# ESP32-S3 register map
Vendor: ESPRESSIF SYSTEMS (SHANGHAI) CO., LTD.; Series: ESP32 S-Series; File version: 22
CPU: Xtensa LX7 r0p0, little endian, no MPU, FPU, 0 interrupt priority bits
Address unit: 32 bits
Registers are 32-bit, read-write, reset 0x0 unless marked. A register's access mark holds for its fields unless they carry their own. Offsets are from the block's base; [hi:lo] are bit positions; {n}, {i} and the like mark numbered series.

## ASSIST_DEBUG — Debug Assist
Base 0x600CE000
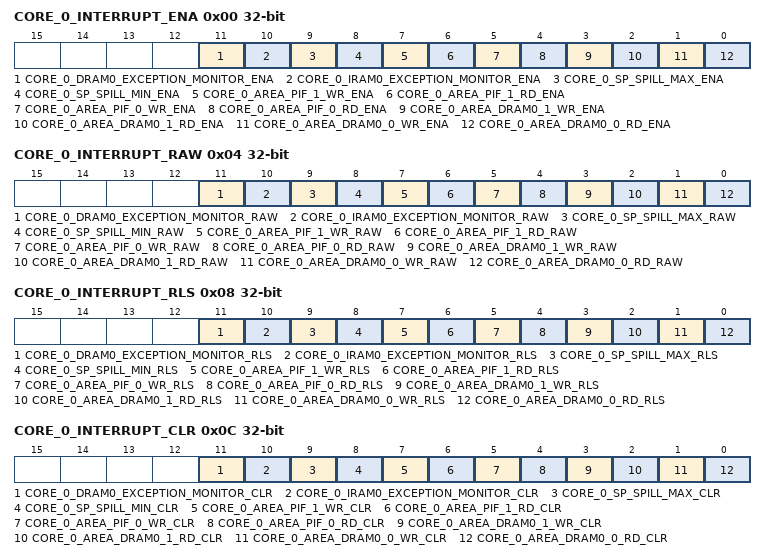
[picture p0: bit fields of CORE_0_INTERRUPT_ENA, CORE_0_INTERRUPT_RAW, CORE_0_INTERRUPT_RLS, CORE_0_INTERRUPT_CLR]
0x00 CORE_0_INTERRUPT_ENA — core0 monitor enable configuration register
  [11] CORE_0_DRAM0_EXCEPTION_MONITOR_ENA — DBUS busy monitor enbale
  [10] CORE_0_IRAM0_EXCEPTION_MONITOR_ENA — IBUS busy monitor enable
  [9] CORE_0_SP_SPILL_MAX_ENA — Core0 stackpoint underflow monitor enable
  [8] CORE_0_SP_SPILL_MIN_ENA — Core0 stackpoint overflow monitor enable
  [7] CORE_0_AREA_PIF_1_WR_ENA — Core0 PIF area1 write monitor enable
  [6] CORE_0_AREA_PIF_1_RD_ENA — Core0 PIF area1 read monitor enable
  [5] CORE_0_AREA_PIF_0_WR_ENA — Core0 PIF area0 write monitor enable
  [4] CORE_0_AREA_PIF_0_RD_ENA — Core0 PIF area0 read monitor enable
  [3] CORE_0_AREA_DRAM0_1_WR_ENA — Core0 dram0 area1 write monitor enable
  [2] CORE_0_AREA_DRAM0_1_RD_ENA — Core0 dram0 area1 read monitor enable
  [1] CORE_0_AREA_DRAM0_0_WR_ENA — Core0 dram0 area0 write monitor enable
  [0] CORE_0_AREA_DRAM0_0_RD_ENA — Core0 dram0 area0 read monitor enable
0x04 CORE_0_INTERRUPT_RAW ro — core0 monitor interrupt status register
  [11] CORE_0_DRAM0_EXCEPTION_MONITOR_RAW — DBUS busy monitor initerrupt status
  [10] CORE_0_IRAM0_EXCEPTION_MONITOR_RAW — IBUS busy monitor interrupt status
  [9] CORE_0_SP_SPILL_MAX_RAW — Core0 stackpoint underflow monitor interrupt status
  [8] CORE_0_SP_SPILL_MIN_RAW — Core0 stackpoint overflow monitor interrupt status
  [7] CORE_0_AREA_PIF_1_WR_RAW — Core0 PIF area1 write monitor interrupt status
  [6] CORE_0_AREA_PIF_1_RD_RAW — Core0 PIF area1 read monitor interrupt status
  [5] CORE_0_AREA_PIF_0_WR_RAW — Core0 PIF area0 write monitor interrupt status
  [4] CORE_0_AREA_PIF_0_RD_RAW — Core0 PIF area0 read monitor interrupt status
  [3] CORE_0_AREA_DRAM0_1_WR_RAW — Core0 dram0 area1 write monitor interrupt status
  [2] CORE_0_AREA_DRAM0_1_RD_RAW — Core0 dram0 area1 read monitor interrupt status
  [1] CORE_0_AREA_DRAM0_0_WR_RAW — Core0 dram0 area0 write monitor interrupt status
  [0] CORE_0_AREA_DRAM0_0_RD_RAW — Core0 dram0 area0 read monitor interrupt status
0x08 CORE_0_INTERRUPT_RLS — core0 monitor interrupt enable register
  [11] CORE_0_DRAM0_EXCEPTION_MONITOR_RLS — DBUS busy monitor interrupt enbale
  [10] CORE_0_IRAM0_EXCEPTION_MONITOR_RLS — IBUS busy monitor interrupt enable
  [9] CORE_0_SP_SPILL_MAX_RLS — Core0 stackpoint underflow monitor interrupt enable
  [8] CORE_0_SP_SPILL_MIN_RLS — Core0 stackpoint overflow monitor interrupt enable
  [7] CORE_0_AREA_PIF_1_WR_RLS — Core0 PIF area1 write monitor interrupt enable
  [6] CORE_0_AREA_PIF_1_RD_RLS — Core0 PIF area1 read monitor interrupt enable
  [5] CORE_0_AREA_PIF_0_WR_RLS — Core0 PIF area0 write monitor interrupt enable
  [4] CORE_0_AREA_PIF_0_RD_RLS — Core0 PIF area0 read monitor interrupt enable
  [3] CORE_0_AREA_DRAM0_1_WR_RLS — Core0 dram0 area1 write monitor interrupt enable
  [2] CORE_0_AREA_DRAM0_1_RD_RLS — Core0 dram0 area1 read monitor interrupt enable
  [1] CORE_0_AREA_DRAM0_0_WR_RLS — Core0 dram0 area0 write monitor interrupt enable
  [0] CORE_0_AREA_DRAM0_0_RD_RLS — Core0 dram0 area0 read monitor interrupt enable
0x0C CORE_0_INTERRUPT_CLR — core0 monitor interrupt clr register
  [11] CORE_0_DRAM0_EXCEPTION_MONITOR_CLR — DBUS busy monitor interrupt clr
  [10] CORE_0_IRAM0_EXCEPTION_MONITOR_CLR — IBUS busy monitor interrupt clr
  [9] CORE_0_SP_SPILL_MAX_CLR — Core0 stackpoint underflow monitor interrupt clr
  [8] CORE_0_SP_SPILL_MIN_CLR — Core0 stackpoint overflow monitor interrupt clr
  [7] CORE_0_AREA_PIF_1_WR_CLR — Core0 PIF area1 write monitor interrupt clr
  [6] CORE_0_AREA_PIF_1_RD_CLR — Core0 PIF area1 read monitor interrupt clr
  [5] CORE_0_AREA_PIF_0_WR_CLR — Core0 PIF area0 write monitor interrupt clr
  [4] CORE_0_AREA_PIF_0_RD_CLR — Core0 PIF area0 read monitor interrupt clr
  [3] CORE_0_AREA_DRAM0_1_WR_CLR — Core0 dram0 area1 write monitor interrupt clr
  [2] CORE_0_AREA_DRAM0_1_RD_CLR — Core0 dram0 area1 read monitor interrupt clr
  [1] CORE_0_AREA_DRAM0_0_WR_CLR — Core0 dram0 area0 write monitor interrupt clr
  [0] CORE_0_AREA_DRAM0_0_RD_CLR — Core0 dram0 area0 read monitor interrupt clr
0x10 CORE_0_AREA_DRAM0_0_MIN reset 0xFFFFFFFF — core0 dram0 region0 addr configuration register
  [31:0] CORE_0_AREA_DRAM0_0_MIN — Core0 dram0 region0 start addr
0x14 CORE_0_AREA_DRAM0_0_MAX — core0 dram0 region0 addr configuration register
  [31:0] CORE_0_AREA_DRAM0_0_MAX — Core0 dram0 region0 end addr
0x18 CORE_0_AREA_DRAM0_1_MIN reset 0xFFFFFFFF — core0 dram0 region1 addr configuration register
  [31:0] CORE_0_AREA_DRAM0_1_MIN — Core0 dram0 region1 start addr
0x1C CORE_0_AREA_DRAM0_1_MAX — core0 dram0 region1 addr configuration register
  [31:0] CORE_0_AREA_DRAM0_1_MAX — Core0 dram0 region1 end addr
0x20 CORE_0_AREA_PIF_0_MIN reset 0xFFFFFFFF — core0 PIF region0 addr configuration register
  [31:0] CORE_0_AREA_PIF_0_MIN — Core0 PIF region0 start addr
0x24 CORE_0_AREA_PIF_0_MAX — core0 PIF region0 addr configuration register
  [31:0] CORE_0_AREA_PIF_0_MAX — Core0 PIF region0 end addr
0x28 CORE_0_AREA_PIF_1_MIN reset 0xFFFFFFFF — core0 PIF region1 addr configuration register
  [31:0] CORE_0_AREA_PIF_1_MIN — Core0 PIF region1 start addr
0x2C CORE_0_AREA_PIF_1_MAX — core0 PIF region1 addr configuration register
  [31:0] CORE_0_AREA_PIF_1_MAX — Core0 PIF region1 end addr
0x30 CORE_0_AREA_SP ro reset 0xFFFFFFFF — core0 area sp status register
  [31:0] CORE_0_AREA_SP — the stackpointer when first touch region monitor interrupt
0x34 CORE_0_AREA_PC ro — core0 area pc status register
  [31:0] CORE_0_AREA_PC — the PC when first touch region monitor interrupt
0x38 CORE_0_SP_UNSTABLE reset 0xB — core0 sp unstable configuration register
  [7:0] CORE_0_SP_UNSTABLE — unstable period when window change,during this period no check stackpointer
0x3C CORE_0_SP_MIN — core0 sp region configuration regsiter
  [31:0] CORE_0_SP_MIN — stack min value
0x40 CORE_0_SP_MAX reset 0xFFFFFFFF — core0 sp region configuration regsiter
  [31:0] CORE_0_SP_MAX — stack max value
0x44 CORE_0_SP_PC ro — core0 sp pc status register
  [31:0] CORE_0_SP_PC — the PC when first touch stack monitor interrupt
0x48 CORE_0_RCD_PDEBUGENABLE — core0 pdebug configuration register
  [0] CORE_0_RCD_PDEBUGENABLE — Core0 Pdebugenable,set 1 to open core0 Pdebug interface,then can get core0 PC
0x4C CORE_0_RCD_RECORDING — core0 pdebug status register
  [0] CORE_0_RCD_RECORDING — Pdebug record enable,set 1 to record core0 pdebug interface signal
0x50 CORE_0_RCD_PDEBUGINST ro — core0 pdebug status register
  [31:0] CORE_0_RCD_PDEBUGINST — core0 pdebuginst
0x54 CORE_0_RCD_PDEBUGSTATUS ro — core0 pdebug status register
  [7:0] CORE_0_RCD_PDEBUGSTATUS — core0 pdebugstatus
0x58 CORE_0_RCD_PDEBUGDATA ro — core0 pdebug status register
  [31:0] CORE_0_RCD_PDEBUGDATA — core0_pdebugdata
0x5C CORE_0_RCD_PDEBUGPC ro — core0 pdebug status register
  [31:0] CORE_0_RCD_PDEBUGPC — core0_pdebugPC
0x60 CORE_0_RCD_PDEBUGLS0STAT ro — core0 pdebug status register
  [31:0] CORE_0_RCD_PDEBUGLS0STAT — core0_pdebug_s0stat
0x64 CORE_0_RCD_PDEBUGLS0ADDR ro — core0 pdebug status register
  [31:0] CORE_0_RCD_PDEBUGLS0ADDR — core0_pdebug_s0addr
0x68 CORE_0_RCD_PDEBUGLS0DATA ro — core0 pdebug status register
  [31:0] CORE_0_RCD_PDEBUGLS0DATA — core0_pdebug_s0data
0x6C CORE_0_RCD_SP ro — core0 pdebug status register
  [31:0] CORE_0_RCD_SP — core0_stack pointer
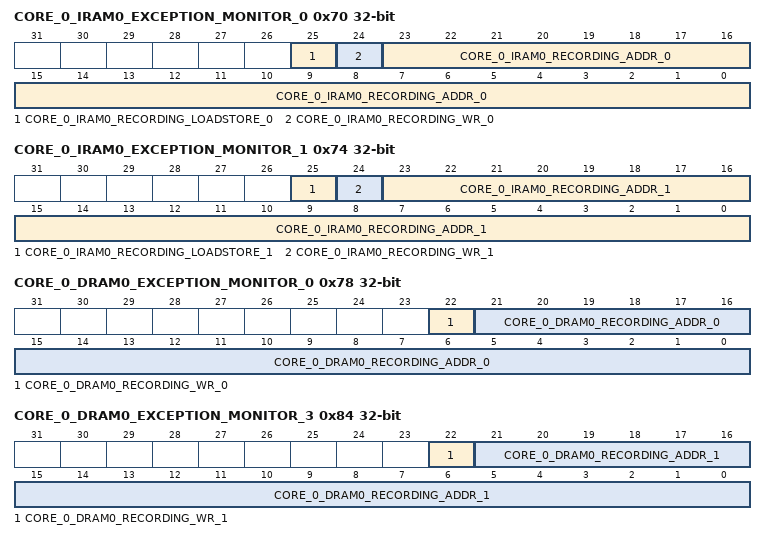
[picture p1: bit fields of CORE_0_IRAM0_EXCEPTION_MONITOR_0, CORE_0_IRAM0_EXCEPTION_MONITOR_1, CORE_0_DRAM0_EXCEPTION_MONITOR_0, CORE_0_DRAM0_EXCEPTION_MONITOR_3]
0x70 CORE_0_IRAM0_EXCEPTION_MONITOR_0 ro — core0 bus busy status regsiter
  [25] CORE_0_IRAM0_RECORDING_LOADSTORE_0 — The first iram0's loadstore status when trigger IRAM busy interrupt
  [24] CORE_0_IRAM0_RECORDING_WR_0 — The first iram0's wr status when trigger IRAM busy interrupt
  [23:0] CORE_0_IRAM0_RECORDING_ADDR_0 — The first iram0's addr[25:2] status when trigger IRAM busy interrupt
0x74 CORE_0_IRAM0_EXCEPTION_MONITOR_1 ro — core0 bus busy status regsiter
  [25] CORE_0_IRAM0_RECORDING_LOADSTORE_1 — The second iram0's loadstore status when trigger IRAM busy interrupt
  [24] CORE_0_IRAM0_RECORDING_WR_1 — The second iram0's wr status when trigger IRAM busy interrupt
  [23:0] CORE_0_IRAM0_RECORDING_ADDR_1 — The second iram0's addr[25:2] status when trigger IRAM busy interrupt
0x78 CORE_0_DRAM0_EXCEPTION_MONITOR_0 ro — core0 bus busy status regsiter
  [22] CORE_0_DRAM0_RECORDING_WR_0 — The first dram0's wr status when trigger DRAM busy interrupt
  [21:0] CORE_0_DRAM0_RECORDING_ADDR_0 — The first dram0's addr[25:4] status when trigger DRAM busy interrupt
0x7C CORE_0_DRAM0_EXCEPTION_MONITOR_1 ro — core0 bus busy status regsiter
  [15:0] CORE_0_DRAM0_RECORDING_BYTEEN_0 — The first dram0's byteen status when trigger DRAM busy interrupt
0x80 CORE_0_DRAM0_EXCEPTION_MONITOR_2 ro reset 0xFFFFFFFF — core0 bus busy status regsiter
  [31:0] CORE_0_DRAM0_RECORDING_PC_0 — The first dram0's PC status when trigger DRAM busy interrupt
0x84 CORE_0_DRAM0_EXCEPTION_MONITOR_3 ro — core0 bus busy status regsiter
  [22] CORE_0_DRAM0_RECORDING_WR_1 — The second dram0's wr status when trigger DRAM busy interrupt
  [21:0] CORE_0_DRAM0_RECORDING_ADDR_1 — The second dram0's addr[25:4] status when trigger DRAM busy interrupt
0x88 CORE_0_DRAM0_EXCEPTION_MONITOR_4 ro — core0 bus busy configuration regsiter
  [15:0] CORE_0_DRAM0_RECORDING_BYTEEN_1 — The second dram0's byteen status when trigger DRAM busy interrupt
0x8C CORE_0_DRAM0_EXCEPTION_MONITOR_5 ro reset 0xFFFFFFFF — core0 bus busy configuration regsiter
  [31:0] CORE_0_DRAM0_RECORDING_PC_1 — The second dram0's PC status when trigger DRAM busy interrupt
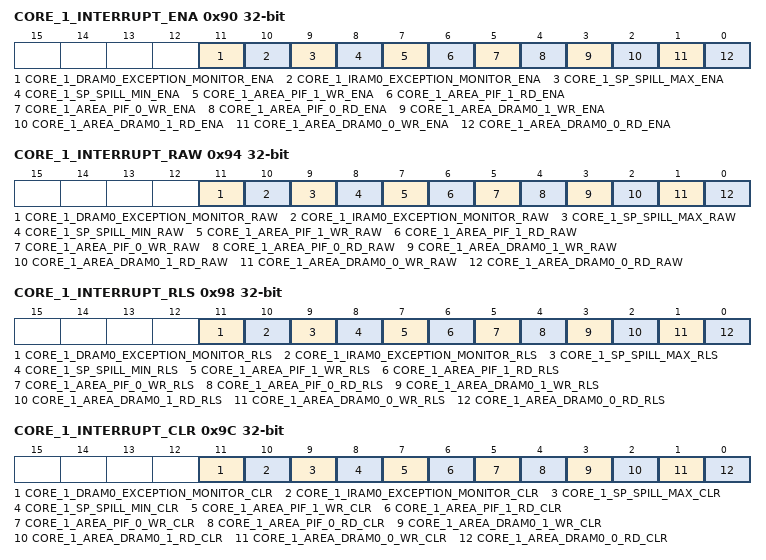
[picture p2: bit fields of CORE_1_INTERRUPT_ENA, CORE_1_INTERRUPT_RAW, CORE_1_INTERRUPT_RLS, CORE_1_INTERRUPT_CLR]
0x90 CORE_1_INTERRUPT_ENA — Core1 monitor enable configuration register
  [11] CORE_1_DRAM0_EXCEPTION_MONITOR_ENA — DBUS busy monitor enbale
  [10] CORE_1_IRAM0_EXCEPTION_MONITOR_ENA — IBUS busy monitor enable
  [9] CORE_1_SP_SPILL_MAX_ENA — Core1 stackpoint underflow monitor enable
  [8] CORE_1_SP_SPILL_MIN_ENA — Core1 stackpoint overflow monitor enable
  [7] CORE_1_AREA_PIF_1_WR_ENA — Core1 PIF area1 write monitor enable
  [6] CORE_1_AREA_PIF_1_RD_ENA — Core1 PIF area1 read monitor enable
  [5] CORE_1_AREA_PIF_0_WR_ENA — Core1 PIF area0 write monitor enable
  [4] CORE_1_AREA_PIF_0_RD_ENA — Core1 PIF area0 read monitor enable
  [3] CORE_1_AREA_DRAM0_1_WR_ENA — Core1 dram0 area1 write monitor enable
  [2] CORE_1_AREA_DRAM0_1_RD_ENA — Core1 dram0 area1 read monitor enable
  [1] CORE_1_AREA_DRAM0_0_WR_ENA — Core1 dram0 area0 write monitor enable
  [0] CORE_1_AREA_DRAM0_0_RD_ENA — Core1 dram0 area0 read monitor enable
0x94 CORE_1_INTERRUPT_RAW ro — Core1 monitor interrupt status register
  [11] CORE_1_DRAM0_EXCEPTION_MONITOR_RAW — DBUS busy monitor initerrupt status
  [10] CORE_1_IRAM0_EXCEPTION_MONITOR_RAW — IBUS busy monitor interrupt status
  [9] CORE_1_SP_SPILL_MAX_RAW — Core1 stackpoint underflow monitor interrupt status
  [8] CORE_1_SP_SPILL_MIN_RAW — Core1 stackpoint overflow monitor interrupt status
  [7] CORE_1_AREA_PIF_1_WR_RAW — Core1 PIF area1 write monitor interrupt status
  [6] CORE_1_AREA_PIF_1_RD_RAW — Core1 PIF area1 read monitor interrupt status
  [5] CORE_1_AREA_PIF_0_WR_RAW — Core1 PIF area0 write monitor interrupt status
  [4] CORE_1_AREA_PIF_0_RD_RAW — Core1 PIF area0 read monitor interrupt status
  [3] CORE_1_AREA_DRAM0_1_WR_RAW — Core1 dram0 area1 write monitor interrupt status
  [2] CORE_1_AREA_DRAM0_1_RD_RAW — Core1 dram0 area1 read monitor interrupt status
  [1] CORE_1_AREA_DRAM0_0_WR_RAW — Core1 dram0 area0 write monitor interrupt status
  [0] CORE_1_AREA_DRAM0_0_RD_RAW — Core1 dram0 area0 read monitor interrupt status
0x98 CORE_1_INTERRUPT_RLS — Core1 monitor interrupt enable register
  [11] CORE_1_DRAM0_EXCEPTION_MONITOR_RLS — DBUS busy monitor interrupt enbale
  [10] CORE_1_IRAM0_EXCEPTION_MONITOR_RLS — IBUS busy monitor interrupt enable
  [9] CORE_1_SP_SPILL_MAX_RLS — Core1 stackpoint underflow monitor interrupt enable
  [8] CORE_1_SP_SPILL_MIN_RLS — Core1 stackpoint overflow monitor interrupt enable
  [7] CORE_1_AREA_PIF_1_WR_RLS — Core1 PIF area1 write monitor interrupt enable
  [6] CORE_1_AREA_PIF_1_RD_RLS — Core1 PIF area1 read monitor interrupt enable
  [5] CORE_1_AREA_PIF_0_WR_RLS — Core1 PIF area0 write monitor interrupt enable
  [4] CORE_1_AREA_PIF_0_RD_RLS — Core1 PIF area0 read monitor interrupt enable
  [3] CORE_1_AREA_DRAM0_1_WR_RLS — Core1 dram0 area1 write monitor interrupt enable
  [2] CORE_1_AREA_DRAM0_1_RD_RLS — Core1 dram0 area1 read monitor interrupt enable
  [1] CORE_1_AREA_DRAM0_0_WR_RLS — Core1 dram0 area0 write monitor interrupt enable
  [0] CORE_1_AREA_DRAM0_0_RD_RLS — Core1 dram0 area0 read monitor interrupt enable
0x9C CORE_1_INTERRUPT_CLR — Core1 monitor interrupt clr register
  [11] CORE_1_DRAM0_EXCEPTION_MONITOR_CLR — DBUS busy monitor interrupt clr
  [10] CORE_1_IRAM0_EXCEPTION_MONITOR_CLR — IBUS busy monitor interrupt clr
  [9] CORE_1_SP_SPILL_MAX_CLR — Core1 stackpoint underflow monitor interrupt clr
  [8] CORE_1_SP_SPILL_MIN_CLR — Core1 stackpoint overflow monitor interrupt clr
  [7] CORE_1_AREA_PIF_1_WR_CLR — Core1 PIF area1 write monitor interrupt clr
  [6] CORE_1_AREA_PIF_1_RD_CLR — Core1 PIF area1 read monitor interrupt clr
  [5] CORE_1_AREA_PIF_0_WR_CLR — Core1 PIF area0 write monitor interrupt clr
  [4] CORE_1_AREA_PIF_0_RD_CLR — Core1 PIF area0 read monitor interrupt clr
  [3] CORE_1_AREA_DRAM0_1_WR_CLR — Core1 dram0 area1 write monitor interrupt clr
  [2] CORE_1_AREA_DRAM0_1_RD_CLR — Core1 dram0 area1 read monitor interrupt clr
  [1] CORE_1_AREA_DRAM0_0_WR_CLR — Core1 dram0 area0 write monitor interrupt clr
  [0] CORE_1_AREA_DRAM0_0_RD_CLR — Core1 dram0 area0 read monitor interrupt clr
0xA0 CORE_1_AREA_DRAM0_0_MIN reset 0xFFFFFFFF — Core1 dram0 region0 addr configuration register
  [31:0] CORE_1_AREA_DRAM0_0_MIN — Core1 dram0 region0 start addr
0xA4 CORE_1_AREA_DRAM0_0_MAX — Core1 dram0 region0 addr configuration register
  [31:0] CORE_1_AREA_DRAM0_0_MAX — Core1 dram0 region0 end addr
0xA8 CORE_1_AREA_DRAM0_1_MIN reset 0xFFFFFFFF — Core1 dram0 region1 addr configuration register
  [31:0] CORE_1_AREA_DRAM0_1_MIN — Core1 dram0 region1 start addr
0xAC CORE_1_AREA_DRAM0_1_MAX — Core1 dram0 region1 addr configuration register
  [31:0] CORE_1_AREA_DRAM0_1_MAX — Core1 dram0 region1 end addr
0xB0 CORE_1_AREA_PIF_0_MIN reset 0xFFFFFFFF — Core1 PIF region0 addr configuration register
  [31:0] CORE_1_AREA_PIF_0_MIN — Core1 PIF region0 start addr
0xB4 CORE_1_AREA_PIF_0_MAX — Core1 PIF region0 addr configuration register
  [31:0] CORE_1_AREA_PIF_0_MAX — Core1 PIF region0 end addr
0xB8 CORE_1_AREA_PIF_1_MIN reset 0xFFFFFFFF — Core1 PIF region1 addr configuration register
  [31:0] CORE_1_AREA_PIF_1_MIN — Core1 PIF region1 start addr
0xBC CORE_1_AREA_PIF_1_MAX — Core1 PIF region1 addr configuration register
  [31:0] CORE_1_AREA_PIF_1_MAX — Core1 PIF region1 end addr
0xC0 CORE_1_AREA_PC ro — Core1 area sp status register
  [31:0] CORE_1_AREA_PC — the stackpointer when first touch region monitor interrupt
0xC4 CORE_1_AREA_SP ro — Core1 area pc status register
  [31:0] CORE_1_AREA_SP — the PC when first touch region monitor interrupt
0xC8 CORE_1_SP_UNSTABLE reset 0xB — Core1 sp unstable configuration register
  [7:0] CORE_1_SP_UNSTABLE — unstable period when window change,during this period no check stackpointer
0xCC CORE_1_SP_MIN — Core1 sp region configuration regsiter
  [31:0] CORE_1_SP_MIN — stack min value
0xD0 CORE_1_SP_MAX reset 0xFFFFFFFF — Core1 sp region configuration regsiter
  [31:0] CORE_1_SP_MAX — stack max value
0xD4 CORE_1_SP_PC ro — Core1 sp pc status register
  [31:0] CORE_1_SP_PC — the PC when first touch stack monitor interrupt
0xD8 CORE_1_RCD_PDEBUGENABLE — Core1 pdebug configuration register
  [0] CORE_1_RCD_PDEBUGENABLE — Core1 Pdebugenable,set 1 to open Core1 Pdebug interface, then can get Core1 PC
0xDC CORE_1_RCD_RECORDING — Core1 pdebug status register
  [0] CORE_1_RCD_RECORDING — Pdebug record enable,set 1 to record Core1 pdebug interface signal
0xE0 CORE_1_RCD_PDEBUGINST ro — Core1 pdebug status register
  [31:0] CORE_1_RCD_PDEBUGINST — Core1 pdebuginst
0xE4 CORE_1_RCD_PDEBUGSTATUS ro — Core1 pdebug status register
  [7:0] CORE_1_RCD_PDEBUGSTATUS — Core1 pdebugstatus
0xE8 CORE_1_RCD_PDEBUGDATA ro — Core1 pdebug status register
  [31:0] CORE_1_RCD_PDEBUGDATA — Core1_pdebugdata
0xEC CORE_1_RCD_PDEBUGPC ro — Core1 pdebug status register
  [31:0] CORE_1_RCD_PDEBUGPC — Core1_pdebugPC
0xF0 CORE_1_RCD_PDEBUGLS0STAT ro — Core1 pdebug status register
  [31:0] CORE_1_RCD_PDEBUGLS0STAT — Core1_pdebug_s0stat
0xF4 CORE_1_RCD_PDEBUGLS0ADDR ro — Core1 pdebug status register
  [31:0] CORE_1_RCD_PDEBUGLS0ADDR — Core1_pdebug_s0addr
0xF8 CORE_1_RCD_PDEBUGLS0DATA ro — Core1 pdebug status register
  [31:0] CORE_1_RCD_PDEBUGLS0DATA — Core1_pdebug_s0data
0xFC CORE_1_RCD_SP ro — Core1 pdebug status register
  [31:0] CORE_1_RCD_SP — Core1_stack pointer
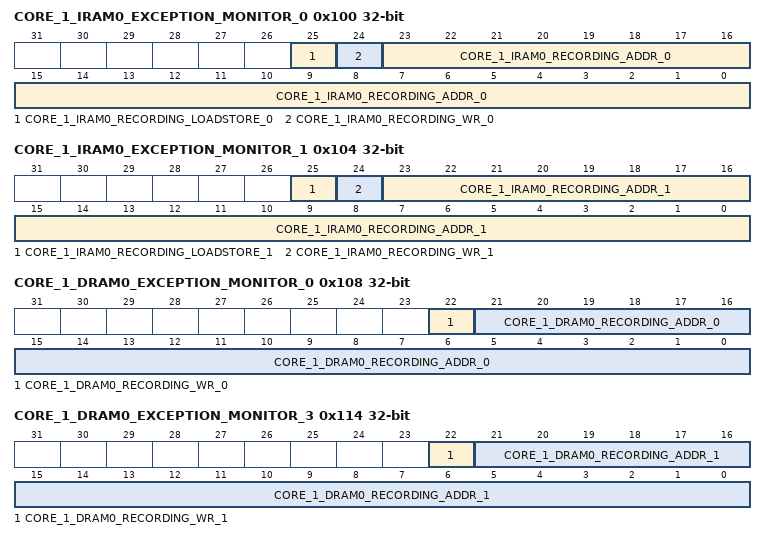
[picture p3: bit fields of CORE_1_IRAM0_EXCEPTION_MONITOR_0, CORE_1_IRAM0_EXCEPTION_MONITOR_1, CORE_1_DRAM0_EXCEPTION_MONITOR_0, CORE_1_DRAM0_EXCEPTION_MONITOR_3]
0x100 CORE_1_IRAM0_EXCEPTION_MONITOR_0 ro — Core1 bus busy status regsiter
  [25] CORE_1_IRAM0_RECORDING_LOADSTORE_0 — The first iram0's loadstore status when trigger IRAM busy interrupt
  [24] CORE_1_IRAM0_RECORDING_WR_0 — The first iram0's wr status when trigger IRAM busy interrupt
  [23:0] CORE_1_IRAM0_RECORDING_ADDR_0 — The first iram0's addr[25:2] status when trigger IRAM busy interrupt
0x104 CORE_1_IRAM0_EXCEPTION_MONITOR_1 ro — Core1 bus busy status regsiter
  [25] CORE_1_IRAM0_RECORDING_LOADSTORE_1 — The second iram0's loadstore status when trigger IRAM busy interrupt
  [24] CORE_1_IRAM0_RECORDING_WR_1 — The second iram0's wr status when trigger IRAM busy interrupt
  [23:0] CORE_1_IRAM0_RECORDING_ADDR_1 — The second iram0's addr[25:2] status when trigger IRAM busy interrupt
0x108 CORE_1_DRAM0_EXCEPTION_MONITOR_0 ro — Core1 bus busy status regsiter
  [22] CORE_1_DRAM0_RECORDING_WR_0 — The first dram0's wr status when trigger DRAM busy interrupt
  [21:0] CORE_1_DRAM0_RECORDING_ADDR_0 — The first dram0's addr[25:4] status when trigger DRAM busy interrupt
0x10C CORE_1_DRAM0_EXCEPTION_MONITOR_1 ro — Core1 bus busy status regsiter
  [15:0] CORE_1_DRAM0_RECORDING_BYTEEN_0 — The first dram0's byteen status when trigger DRAM busy interrupt
0x110 CORE_1_DRAM0_EXCEPTION_MONITOR_2 ro reset 0xFFFFFFFF — Core1 bus busy status regsiter
  [31:0] CORE_1_DRAM0_RECORDING_PC_0 — The first dram0's PC status when trigger DRAM busy interrupt
0x114 CORE_1_DRAM0_EXCEPTION_MONITOR_3 ro — Core1 bus busy status regsiter
  [22] CORE_1_DRAM0_RECORDING_WR_1 — The second dram0's wr status when trigger DRAM busy interrupt
  [21:0] CORE_1_DRAM0_RECORDING_ADDR_1 — The second dram0's addr[25:4] status when trigger DRAM busy interrupt
0x118 CORE_1_DRAM0_EXCEPTION_MONITOR_4 ro — Core1 bus busy status regsiter
  [15:0] CORE_1_DRAM0_RECORDING_BYTEEN_1 — The second dram0's byteen status when trigger DRAM busy interrupt
0x11C CORE_1_DRAM0_EXCEPTION_MONITOR_5 ro reset 0xFFFFFFFF — Core1 bus busy status regsiter
  [31:0] CORE_1_DRAM0_RECORDING_PC_1 — The second dram0's PC status when trigger DRAM busy interrupt
0x120 CORE_X_IRAM0_DRAM0_EXCEPTION_MONITOR_0 reset 0xFFFFF — bus busy configuration register
  [19:0] CORE_X_IRAM0_DRAM0_LIMIT_CYCLE_0 — busy monitor window cycle
0x124 CORE_X_IRAM0_DRAM0_EXCEPTION_MONITOR_1 reset 0xFFFFF — bus busy configuration register
  [19:0] CORE_X_IRAM0_DRAM0_LIMIT_CYCLE_1 — non busy cycle,for example: when cycle=100 and cycle=10,it means that in 100 cycle, if busy access success time less than 10, it will trigger interrutpt
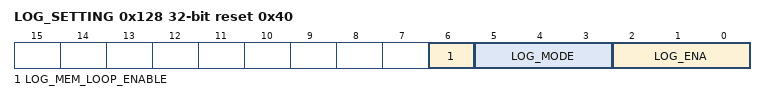
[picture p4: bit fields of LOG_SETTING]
0x128 LOG_SETTING reset 0x40 — log set register
  [6] LOG_MEM_LOOP_ENABLE — mem_loop enable,1 means that loop write
  [5:3] LOG_MODE — check_mode:0:write,1:word,2:halword,3:byte,4:doubleword,5:4word
  [2:0] LOG_ENA — bus moniter enable: [0]Core1,[1]core1,[2]dma
{0x12C+4i} LOG_DATA_{i} (i=0..3) — log check data register
  [31:0] LOG_DATA_{i} — check data{i}
0x13C LOG_DATA_MASK — log check data mask register
  [15:0] LOG_DATA_SIZE — data mask
0x140 LOG_MIN — log check region configuration register
  [31:0] LOG_MIN — check region min addr
0x144 LOG_MAX — log check region configuration register
  [31:0] LOG_MAX — check region max addr
0x148 LOG_MEM_START — log mem region configuration register
  [31:0] LOG_MEM_START — mem start addr
0x14C LOG_MEM_END — log mem region configuration register
  [31:0] LOG_MEM_END — mem end addr
0x150 LOG_MEM_WRITING_ADDR ro — log mem addr status register
  [31:0] LOG_MEM_WRITING_ADDR — mem current addr, it means next writing addr
0x154 LOG_MEM_FULL_FLAG — log mem status register
  [0] LOG_MEM_FULL_FLAG — when it's 1,show that mem write loop morte than one time.
0x1FC DATE reset 0x2003040 — version register
  [27:0] DATE
